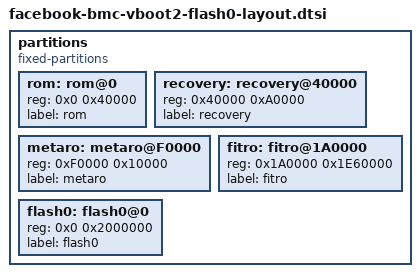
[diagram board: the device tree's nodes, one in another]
// SPDX-License-Identifier: GPL-2.0+
// Copyright (c) 2018 Facebook Inc.

partitions {
	compatible = "fixed-partitions";
	#address-cells = <1>;
	#size-cells = <1>;
	rom: rom@0 {
		reg = <0x0 0x40000>;
		label = "rom";
	};
	recovery: recovery@40000 {
		reg = <0x40000 0xA0000>;
		label = "recovery";
	};
	/* Don't expose envro as it is not used
	envro@E0000 {
		reg = <0xE0000 0x10000>;
		label = "envro";
	};
	*/
	metaro: metaro@F0000 {
		reg = <0xF0000 0x10000>;
		label = "metaro";
	};
	/* Don't expose u-bootro as it is not used 
	u-bootro: u-bootro@100000 {
		reg = <0x100000 0xA0000>;
		label = "u-bootro";
	};
	*/
	fitro: fitro@1A0000 {
		reg = <0x1A0000 0x1E60000>;
		label = "fitro";
	};

	flash0: flash0@0 {
		reg = <0x0 0x2000000>;
		label = "flash0";
	};
};
